# RP2040 register map
Vendor: Raspberry Pi; File version: 0.1
CPU: CM0PLUS r0p1, little endian, MPU, no FPU, VTOR, 2 interrupt priority bits, 26 interrupts
Registers are 32-bit, read-write, reset 0x0 unless marked. A register's access mark holds for its fields unless they carry their own. Offsets are from the block's base; [hi:lo] are bit positions; {n}, {i} and the like mark numbered series; 'fields as' and 'values as' point back to an identical list.

## WATCHDOG
Base 0x40058000
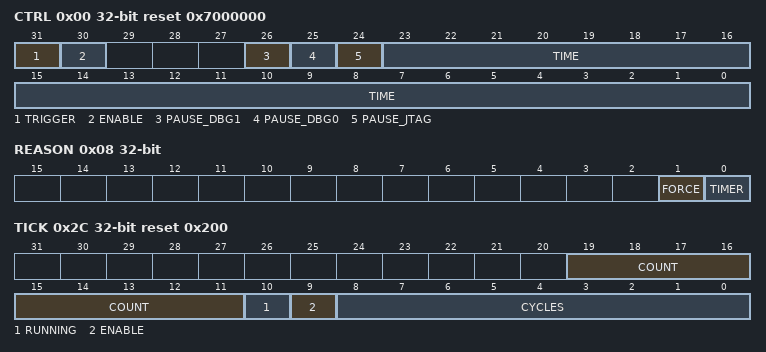
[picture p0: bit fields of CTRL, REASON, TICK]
0x00 CTRL access per field reset 0x7000000 — Watchdog control. The rst_wdsel register determines which subsystems are reset when the watchdog is triggered. The watchdog can be triggered in software.
  [31] TRIGGER rw write-clears — Trigger a watchdog reset
  [30] ENABLE rw — When not enabled the watchdog timer is paused
  [26] PAUSE_DBG1 rw — Pause the watchdog timer when processor 1 is in debug mode
  [25] PAUSE_DBG0 rw — Pause the watchdog timer when processor 0 is in debug mode
  [24] PAUSE_JTAG rw — Pause the watchdog timer when JTAG is accessing the bus fabric
  [23:0] TIME ro — Indicates the number of ticks / 2 (see errata RP2040-E1) before a watchdog reset will be triggered
0x04 LOAD wo — Load the watchdog timer. The maximum setting is 0xffffff which corresponds to 0xffffff / 2 ticks before triggering a watchdog reset (see errata RP2040-E1).
  [23:0] LOAD
0x08 REASON ro — Logs the reason for the last reset. Both bits are zero for the case of a hardware reset.
  [1] FORCE, [0] TIMER
{0xC+4i} SCRATCH{i} (i=0..7) — Scratch register. Information persists through soft reset of the chip.
0x2C TICK access per field reset 0x200 — Controls the tick generator
  [19:11] COUNT ro — Count down timer: the remaining number clk_tick cycles before the next tick is generated.
  [10] RUNNING ro — Is the tick generator running?
  [9] ENABLE rw — start / stop tick generation
  [8:0] CYCLES rw — Total number of clk_tick cycles before the next tick.

## RTC — Register block to control RTC
Base 0x4005C000
0x00 CLKDIV_M1 — Divider minus 1 for the 1 second counter. Safe to change the value when RTC is not enabled.
  [15:0] CLKDIV_M1
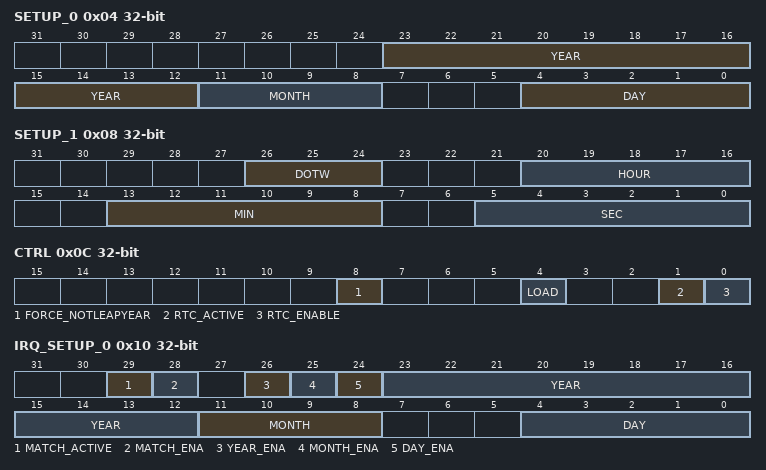
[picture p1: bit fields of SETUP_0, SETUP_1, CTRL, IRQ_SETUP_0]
0x04 SETUP_0 — RTC setup register 0
  [23:12] YEAR
  [11:8] MONTH — Month (1..12)
  [4:0] DAY — Day of the month (1..31)
0x08 SETUP_1 — RTC setup register 1
  [26:24] DOTW — Day of the week: 1-Monday...0-Sunday ISO 8601 mod 7
  [20:16] HOUR — Hours
  [13:8] MIN — Minutes
  [5:0] SEC — Seconds
0x0C CTRL access per field — RTC Control and status
  [8] FORCE_NOTLEAPYEAR rw — If set, leapyear is forced off. Useful for years divisible by 100 but not by 400
  [4] LOAD rw write-clears — Load RTC
  [1] RTC_ACTIVE ro — RTC enabled (running)
  [0] RTC_ENABLE rw — Enable RTC
0x10 IRQ_SETUP_0 access per field — Interrupt setup register 0
  [29] MATCH_ACTIVE ro
  [28] MATCH_ENA rw — Global match enable. Don't change any other value while this one is enabled
  [26] YEAR_ENA rw — Enable year matching
  [25] MONTH_ENA rw — Enable month matching
  [24] DAY_ENA rw — Enable day matching
  [23:12] YEAR rw
  [11:8] MONTH rw — Month (1..12)
  [4:0] DAY rw — Day of the month (1..31)
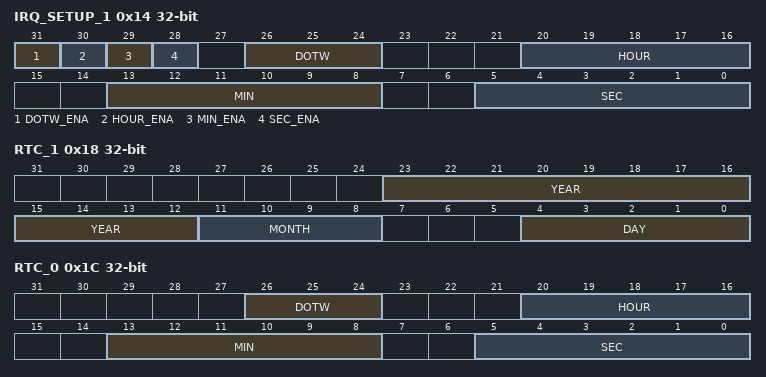
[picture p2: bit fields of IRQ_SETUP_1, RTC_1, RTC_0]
0x14 IRQ_SETUP_1 — Interrupt setup register 1
  [31] DOTW_ENA — Enable day of the week matching
  [30] HOUR_ENA — Enable hour matching
  [29] MIN_ENA — Enable minute matching
  [28] SEC_ENA — Enable second matching
  [26:24] DOTW — Day of the week
  [20:16] HOUR — Hours
  [13:8] MIN — Minutes
  [5:0] SEC — Seconds
0x18 RTC_1 ro — RTC register 1.
  fields as SETUP_0
0x1C RTC_0 ro — RTC register 0. Read this before RTC 1!
  [26:24] DOTW — Day of the week
  [20:16] HOUR — Hours
  [13:8] MIN — Minutes
  [5:0] SEC — Seconds
0x20 INTR ro — Raw Interrupts
  [0] RTC
0x24 INTE — Interrupt Enable
  [0] RTC
0x28 INTF — Interrupt Force
  [0] RTC
0x2C INTS ro — Interrupt status after masking & forcing
  [0] RTC

## VREG_AND_CHIP_RESET — control and status for on-chip voltage regulator and chip level reset subsystem
Base 0x40064000
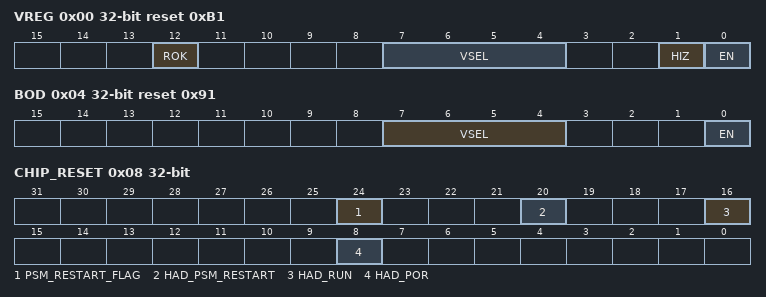
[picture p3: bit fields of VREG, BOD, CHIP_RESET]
0x00 VREG access per field reset 0xB1 — Voltage regulator control and status
  [12] ROK ro — regulation status. 0=not in regulation, 1=in regulation
  [7:4] VSEL rw — output voltage select. 0000 to 0101 - 0.80V. 0110 - 0.85V. 0111 - 0.90V. 1000 - 0.95V. 1001 - 1.00V. 1010 - 1.05V. 1011 - 1.10V (default). 1100 - 1.15V. 1101 - 1.20V. 1110 - 1.25V. 1111 - 1.30V
  [1] HIZ rw — high impedance mode select. 0=not in high impedance mode, 1=in high impedance mode
  [0] EN rw — enable. 0=not enabled, 1=enabled
0x04 BOD reset 0x91 — brown-out detection control
  [7:4] VSEL — threshold select. 0000 - 0.473V. 0001 - 0.516V. 0010 - 0.559V. 0011 - 0.602V. 0100 - 0.645V. 0101 - 0.688V. 0110 - 0.731V. 0111 - 0.774V. 1000 - 0.817V. 1001 - 0.860V (default). 1010 - 0.903V. 1011 - 0.946V. 1100 - 0.989V. 1101 - 1.032V. 1110 - 1.075V. 1111 - 1.118V
  [0] EN — enable. 0=not enabled, 1=enabled
0x08 CHIP_RESET access per field — Chip reset control and status
  [24] PSM_RESTART_FLAG rw write-1-clears — This is set by psm_restart from the debugger. Its purpose is to branch bootcode to a safe mode when the debugger has issued a psm_restart in order to recover from a boot lock-up. In the safe mode the debugger can repair the boot code, clear this flag then reboot the processor.
  [20] HAD_PSM_RESTART ro — Last reset was from the debug port
  [16] HAD_RUN ro — Last reset was from the RUN pin
  [8] HAD_POR ro — Last reset was from the power-on reset or brown-out detection blocks

## TBMAN — Testbench manager. Allows the programmer to know what platform their software is running on.
Base 0x4006C000
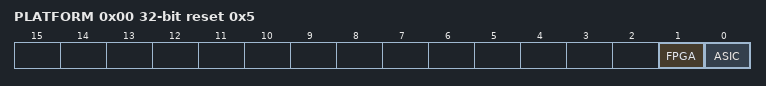
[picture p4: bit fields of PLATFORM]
0x00 PLATFORM ro reset 0x5 — Indicates the type of platform in use
  [1] FPGA — Indicates the platform is an FPGA
  [0] ASIC — Indicates the platform is an ASIC

## USBCTRL_DPRAM — DPRAM layout for USB device.
Base 0x50100000
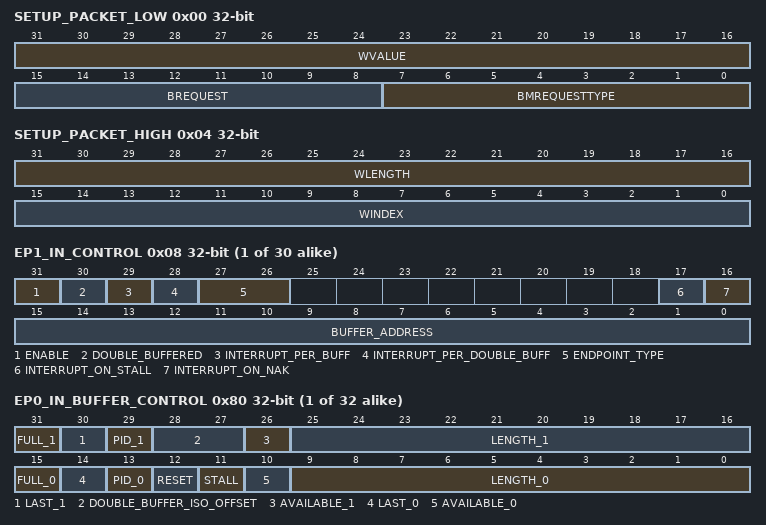
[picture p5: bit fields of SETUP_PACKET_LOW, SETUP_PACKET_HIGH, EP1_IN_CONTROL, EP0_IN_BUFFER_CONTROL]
0x00 SETUP_PACKET_LOW — Bytes 0-3 of the SETUP packet from the host.
  [31:16] WVALUE, [15:8] BREQUEST, [7:0] BMREQUESTTYPE
0x04 SETUP_PACKET_HIGH — Bytes 4-7 of the setup packet from the host.
  [31:16] WLENGTH, [15:0] WINDEX
0x08 EP{x}_CONTROL (x=1_IN,1_OUT,2_IN,2_OUT,3_IN,3_OUT,4_IN,4_OUT,5_IN,5_OUT,6_IN,6_OUT,7_IN,7_OUT,8_IN,8_OUT,9_IN,9_OUT,10_IN,10_OUT,11_IN,11_OUT,12_IN,12_OUT,13_IN,13_OUT,14_IN,14_OUT,15_IN,15_OUT; step 0x4)
  [31] ENABLE — Enable this endpoint. The device will not reply to any packets for this endpoint if this bit is not set.
  [30] DOUBLE_BUFFERED — This endpoint is double buffered.
  [29] INTERRUPT_PER_BUFF — Trigger an interrupt each time a buffer is done.
  [28] INTERRUPT_PER_DOUBLE_BUFF — Trigger an interrupt each time both buffers are done. Only valid in double buffered mode.
  [27:26] ENDPOINT_TYPE
    0=Control; 1=Isochronous; 2=Bulk; 3=Interrupt
  [17] INTERRUPT_ON_STALL — Trigger an interrupt if a STALL is sent. Intended for debug only.
  [16] INTERRUPT_ON_NAK — Trigger an interrupt if a NAK is sent. Intended for debug only.
  [15:0] BUFFER_ADDRESS — 64 byte aligned buffer address for this EP (bits 0-5 are ignored). Relative to the start of the DPRAM.
0x80 EP{x}_BUFFER_CONTROL (x=0_IN,0_OUT,1_IN,1_OUT,2_IN,2_OUT,3_IN,3_OUT,4_IN,4_OUT,5_IN,5_OUT,6_IN,6_OUT,7_IN,7_OUT,8_IN,8_OUT,9_IN,9_OUT,10_IN,10_OUT,11_IN,11_OUT,12_IN,12_OUT,13_IN,13_OUT,14_IN,14_OUT,15_IN,15_OUT; step 0x4) — Buffer control for both buffers of an endpoint. Fields ending in a _1 are for buffer 1. Fields ending in a _0 are for buffer 0. Buffer 1 controls are only valid if the endpoint is in double buffered mode.
  [31] FULL_1 — Buffer 1 is full. For an IN transfer (TX to the host) the bit is set to indicate the data is valid. For an OUT transfer (RX from the host) this bit should be left as a 0. The host will set it when it has filled the buffer with data.
  [30] LAST_1 — Buffer 1 is the last buffer of the transfer.
  [29] PID_1 — The data pid of buffer 1.
  [28:27] DOUBLE_BUFFER_ISO_OFFSET — The number of bytes buffer 1 is offset from buffer 0 in Isochronous mode. Only valid in double buffered mode for an Isochronous endpoint. For a non Isochronous endpoint the offset is always 64 bytes.
    0=128; 1=256; 2=512; 3=1024
  [26] AVAILABLE_1 — Buffer 1 is available. This bit is set to indicate the buffer can be used by the controller. The controller clears the available bit when writing the status back.
  [25:16] LENGTH_1 — The length of the data in buffer 1.
  [15] FULL_0 — Buffer 0 is full. For an IN transfer (TX to the host) the bit is set to indicate the data is valid. For an OUT transfer (RX from the host) this bit should be left as a 0. The host will set it when it has filled the buffer with data.
  [14] LAST_0 — Buffer 0 is the last buffer of the transfer.
  [13] PID_0 — The data pid of buffer 0.
  [12] RESET — Reset the buffer selector to buffer 0.
  [11] STALL — Reply with a stall (valid for both buffers).
  [10] AVAILABLE_0 — Buffer 0 is available. This bit is set to indicate the buffer can be used by the controller. The controller clears the available bit when writing the status back.
  [9:0] LENGTH_0 — The length of the data in buffer 0.

## Notices in the file
Copyright (c) 2020 Raspberry Pi (Trading) Ltd.
SPDX-License-Identifier: BSD-3-Clause
